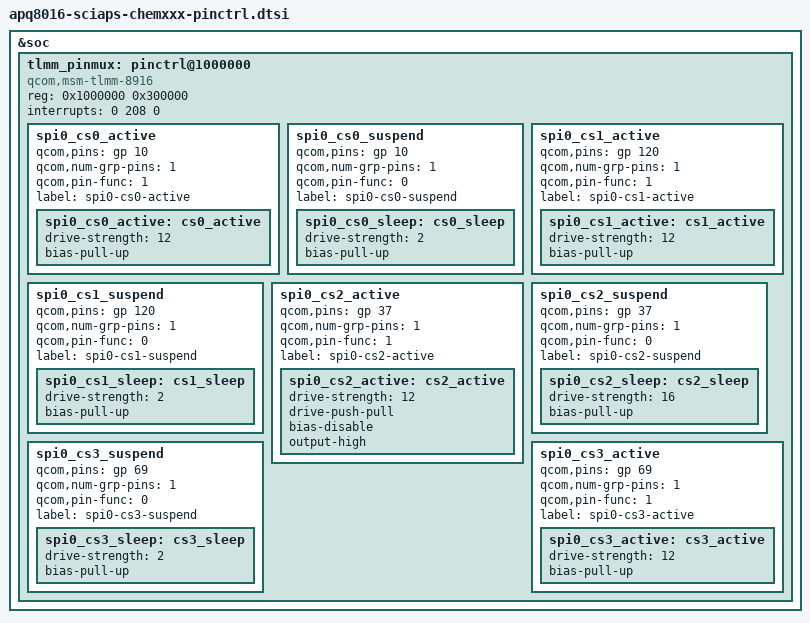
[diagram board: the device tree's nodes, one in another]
/* Copyright (c) 2013-2015, The Linux Foundation. All rights reserved.
 *
 * This program is free software; you can redistribute it and/or modify
 * it under the terms of the GNU General Public License version 2 and
 * only version 2 as published by the Free Software Foundation.
 *
 * This program is distributed in the hope that it will be useful,
 * but WITHOUT ANY WARRANTY; without even the implied warranty of
 * MERCHANTABILITY or FITNESS FOR A PARTICULAR PURPOSE.  See the
 * GNU General Public License for more details.
 */

&soc {
	tlmm_pinmux: pinctrl@1000000 {
		compatible = "qcom,msm-tlmm-8916";
		reg = <0x1000000 0x300000>;
		interrupts = <0 208 0>;

		spi0_cs0_active {
			/* CS */
			qcom,pins = <&gp 10>;
			qcom,num-grp-pins = <1>;
			qcom,pin-func = <1>;
			label = "spi0-cs0-active";
			spi0_cs0_active: cs0_active {
				drive-strength = <12>;
				bias-pull-up; /* pull up */
			};
		};


		spi0_cs0_suspend {
			/* CS */
			qcom,pins = <&gp 10>;
			qcom,num-grp-pins = <1>;
			qcom,pin-func = <0>;
			label = "spi0-cs0-suspend";
			spi0_cs0_sleep: cs0_sleep {
				drive-strength = <2>;
				bias-pull-up; /* pull up */
			};
		};

		spi0_cs1_active {
			/* CS */
			qcom,pins = <&gp 120>;
			qcom,num-grp-pins = <1>;
			qcom,pin-func = <1>;
			label = "spi0-cs1-active";
			spi0_cs1_active: cs1_active {
				drive-strength = <12>;
				bias-pull-up; /* pull up */
			};
		};


		spi0_cs1_suspend {
			/* CS */
			qcom,pins = <&gp 120>;
			qcom,num-grp-pins = <1>;
			qcom,pin-func = <0>;
			label = "spi0-cs1-suspend";
			spi0_cs1_sleep: cs1_sleep {
				drive-strength = <2>;
				bias-pull-up; /* pull up */
			};
		};

		spi0_cs2_active {
			/* CS */
			qcom,pins = <&gp 37>;
			qcom,num-grp-pins = <1>;
			qcom,pin-func = <1>;
			label = "spi0-cs2-active";
			spi0_cs2_active: cs2_active {
				drive-strength = <12>;
				drive-push-pull;
				bias-disable;
				output-high;
				//bias-pull-up; /* pull up */
			};
		};


		spi0_cs2_suspend {
			/* CS */
			qcom,pins = <&gp 37>;
			qcom,num-grp-pins = <1>;
			qcom,pin-func = <0>;
			label = "spi0-cs2-suspend";
			spi0_cs2_sleep: cs2_sleep {
				drive-strength = <16>;
				bias-pull-up; /* pull up */
			};
		};

		spi0_cs3_active {
			/* CS */
			qcom,pins = <&gp 69>;
			qcom,num-grp-pins = <1>;
			qcom,pin-func = <1>;
			label = "spi0-cs3-active";
			spi0_cs3_active: cs3_active {
				drive-strength = <12>;
				bias-pull-up; /* pull up */
			};
		};


		spi0_cs3_suspend {
			/* CS */
			qcom,pins = <&gp 69>;
			qcom,num-grp-pins = <1>;
			qcom,pin-func = <0>;
			label = "spi0-cs3-suspend";
			spi0_cs3_sleep: cs3_sleep {
				drive-strength = <2>;
				bias-pull-up; /* pull up */
			};
		};

	};
};
